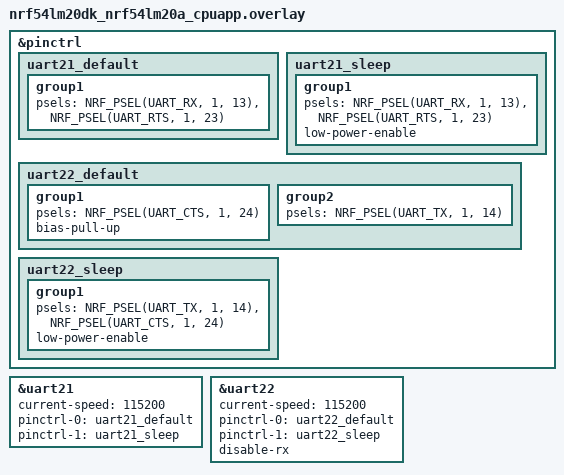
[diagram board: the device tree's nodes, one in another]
/* SPDX-License-Identifier: Apache-2.0 */

&pinctrl {
	uart21_default: uart21_default {
		group1 {
			psels = <NRF_PSEL(UART_RX, 1, 13)>,
				<NRF_PSEL(UART_RTS, 1, 23)>;
		};
	};

	uart21_sleep: uart21_sleep {
		group1 {
			psels = <NRF_PSEL(UART_RX, 1, 13)>,
				<NRF_PSEL(UART_RTS, 1, 23)>;
			low-power-enable;
		};
	};

	uart22_default: uart22_default {
		group1 {
			psels = <NRF_PSEL(UART_CTS, 1, 24)>;
			bias-pull-up;
		};
		group2 {
			psels = <NRF_PSEL(UART_TX, 1, 14)>;
		};
	};

	uart22_sleep: uart22_sleep {
		group1 {
			psels = <NRF_PSEL(UART_TX, 1, 14)>,
				<NRF_PSEL(UART_CTS, 1, 24)>;
			low-power-enable;
		};
	};
};

dut: &uart21 {
	status = "okay";
	current-speed = <115200>;
	pinctrl-0 = <&uart21_default>;
	pinctrl-1 = <&uart21_sleep>;
	pinctrl-names = "default", "sleep";
};

dut_aux: &uart22 {
	status = "okay";
	current-speed = <115200>;
	pinctrl-0 = <&uart22_default>;
	pinctrl-1 = <&uart22_sleep>;
	pinctrl-names = "default", "sleep";
	disable-rx;
};
